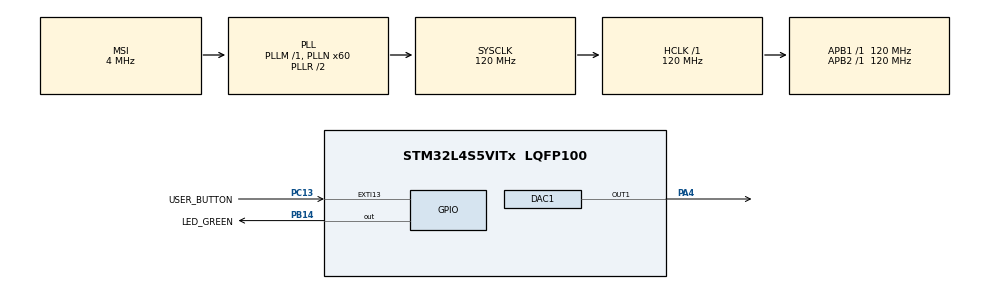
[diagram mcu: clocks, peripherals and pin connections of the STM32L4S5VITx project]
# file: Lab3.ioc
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DAC1.DAC_Trigger-DAC_OUT1=DAC_TRIGGER_T2_TRGO
Dma.DAC1_CH1.0.Direction=DMA_MEMORY_TO_PERIPH
Dma.DAC1_CH1.0.EventEnable=DISABLE
Dma.DAC1_CH1.0.Instance=DMA1_Channel1
Dma.DAC1_CH1.0.MemDataAlignment=DMA_MDATAALIGN_BYTE
Dma.DAC1_CH1.0.MemInc=DMA_MINC_ENABLE
Dma.DAC1_CH1.0.Mode=DMA_CIRCULAR
Dma.DAC1_CH1.0.PeriphDataAlignment=DMA_PDATAALIGN_HALFWORD
Dma.DAC1_CH1.0.PeriphInc=DMA_PINC_DISABLE
Dma.DAC1_CH1.0.Polarity=HAL_DMAMUX_REQUEST_GEN_RISING
Dma.DAC1_CH1.0.Priority=DMA_PRIORITY_LOW
Dma.DAC1_CH1.0.RequestNumber=1
Dma.DAC1_CH1.0.SignalID=NONE
Dma.DAC1_CH1.0.SyncEnable=DISABLE
Dma.DAC1_CH1.0.SyncPolarity=HAL_DMAMUX_SYNC_NO_EVENT
Dma.DAC1_CH1.0.SyncRequestNumber=1
Dma.DAC1_CH1.0.SyncSignalID=NONE
Dma.Request0=DAC1_CH1
Mcu.Family=STM32L4
Mcu.Name=STM32L4S5VITx
Mcu.Package=LQFP100
NVIC.DMA1_Channel1_IRQn=true\:0\:0\:false\:false\:true\:false\:true
NVIC.EXTI15_10_IRQn=true\:0\:0\:false\:false\:true\:true\:true
NVIC.PriorityGroup=NVIC_PRIORITYGROUP_4
NVIC.TIM2_IRQn=true\:0\:0\:false\:false\:true\:true\:true
PA13\ (JTMS/SWDIO).Signal=SYS_JTMS-SWDIO
PA4.Signal=COMP_DAC11_group
PB14.GPIO_Label=LED_GREEN
PB14.Signal=GPIO_Output
PB3\ (JTDO/TRACESWO).Signal=SYS_JTDO-SWO
PC13.GPIO_Label=USER_BUTTON
PC13.Signal=GPXTI13
ProjectManager.HeapSize=0x200
ProjectManager.StackSize=0x400
ProjectManager.TargetToolchain=STM32CubeIDE
RCC.ADCFreq_Value=48000000
RCC.AHBFreq_Value=120000000
RCC.APB1Freq_Value=120000000
RCC.APB1TimFreq_Value=120000000
RCC.APB2Freq_Value=120000000
RCC.APB2TimFreq_Value=120000000
RCC.CortexFreq_Value=120000000
RCC.HCLKFreq_Value=120000000
RCC.HSE_VALUE=8000000
RCC.HSI48_VALUE=48000000
RCC.HSI_VALUE=16000000
RCC.LSE_VALUE=32768
RCC.MSI_VALUE=4000000
RCC.PLLN=60
RCC.PLLSAI1N=24
RCC.SYSCLKFreq_VALUE=120000000
RCC.SYSCLKSource=RCC_SYSCLKSOURCE_PLLCLK
RCC.USBFreq_Value=48000000
RCC.VCOOutputFreq_Value=240000000
SH.COMP_DAC11_group.0=DAC1_OUT1,DAC_OUT1
TIM2.Period=2721
TIM2.TIM_MasterOutputTrigger=TIM_TRGO_UPDATE
VP_TIM2_VS_ClockSourceINT.Mode=Internal
board=B-L4S5I-IOT01A

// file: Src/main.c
/* USER CODE BEGIN Header */
/**
  ******************************************************************************
  * @file           : main.c
  * @brief          : Main program body
  ******************************************************************************
  * @attention
  *
  * <h2><center>&copy; Copyright (c) 2021 STMicroelectronics.
  * All rights reserved.</center></h2>
  *
  * This software component is licensed by ST under BSD 3-Clause license,
  * the "License"; You may not use this file except in compliance with the
  * License. You may obtain a copy of the License at:
  *                        opensource.org/licenses/BSD-3-Clause
  *
  ******************************************************************************
  */
/* USER CODE END Header */
#include "main.h"

/* USER CODE BEGIN Includes */
#include "arm_math.h"
/* USER CODE END Includes */

/* USER CODE BEGIN PD */
#define ITM_Port32(n) (*((volatile unsigned long *) (0xE0000000+4*n)))
uint8_t triangle;
uint8_t saw;
uint8_t sine;
// sample rate: 44.1kHz, system clock freq: 120MHz, counter period
#define first_sample_number 44	// 44.1kHz / 1kHz = 44, C6
#define second_sample_number 33	// 44.1kHz / 1.318kHz = 33, E6
#define third_sample_number 22 // 44.1kHz / 22 = 2.005kHz
#define buffer_length 132	// Buffer length
uint8_t first_array[buffer_length];	// This is the array used to store all C6 values in a period
uint8_t second_array[buffer_length]; // This is the array used to store all E6 values in a period
uint8_t third_array[buffer_length]; // This is the array used to store all values of the third frequency in a period
uint8_t buffer_array[buffer_length]; // This is the array used to store all buffer values in a period
int number = 0;	// This is the global variable to examine the current position
int tone = 0;	// This is the global variable to examine the current tone played
int currentTone = 3;	// This is the global variable to record the current tone
int previousButtonState = GPIO_PIN_RESET;	//This is the global variable to store the previous button state(not pressed)
/* USER CODE END PD */

DAC_HandleTypeDef hdac1;
DMA_HandleTypeDef hdma_dac1_ch1;

TIM_HandleTypeDef htim2;

void SystemClock_Config(void);
static void MX_GPIO_Init(void);
static void MX_DMA_Init(void);
static void MX_DAC1_Init(void);
static void MX_TIM2_Init(void);
/* USER CODE BEGIN PFP */
void HAL_GPIO_EXTI_Callback(uint16_t GPIO_Pin);
void HAL_TIM_PeriodElapsedCallback (TIM_HandleTypeDef * htim);
void HAL_DAC_ConvHalfCpltCallbackCh1(DAC_HandleTypeDef * hdac);
void HAL_DAC_ConvCpltCallbackCh1 (DAC_HandleTypeDef * hdac);
/* USER CODE END PFP */

int main(void)
{

  /* MCU Configuration--------------------------------------------------------*/

  /* Reset of all peripherals, Initializes the Flash interface and the Systick. */
  HAL_Init();

  /* Configure the system clock */
  SystemClock_Config();

  /* Initialize all configured peripherals */
  MX_GPIO_Init();
  MX_DMA_Init();
  MX_DAC1_Init();
  MX_TIM2_Init();
  /* USER CODE BEGIN 2 */
  // Part 2
  int loop = 0;
  float32_t counter = 0;
  float32_t radian = 0;
  float32_t temp = 0;
  for (loop = 0; loop < 3; loop++) {
	  for (counter = 0; counter < first_sample_number; counter++) {
	  	  radian = counter * 8.2 / 180 * PI;	// 360 / 44 = 8.2
	  	  temp = arm_sin_f32(radian); // -1 to 1
	  	  sine = (uint8_t)((temp + 1) * 127 * (2.0 / 3)); // change -1 to 1 to 0 to 2 then scale to 0 to 254, Scale your DAC values so they vary over about 2/3 of the possible dynamic range
	  	  first_array[44 * loop + (int)counter] = sine;
	    }
  }

  for (loop = 0; loop < 4; loop++) {
	  for (counter = 0; counter < second_sample_number; counter++) {
	  	  radian = counter * 10.9 / 180 * PI;	// 360 / 33 = 10.9
	  	  temp = arm_sin_f32(radian); // -1 to 1
	  	  sine = (uint8_t)((temp + 1) * 127 * (2.0 / 3)); // change -1 to 1 to 0 to 2 then scale to 0 to 254, Scale your DAC values so they vary over about 2/3 of the possible dynamic range
	  	  second_array[33 * loop + (int)counter] = sine;
	    }
  }

  for (loop = 0; loop < 6; loop++) {
	  for (counter = 0; counter < third_sample_number; counter++) {
	  	  radian = counter * 16.4 / 180 * PI;	// 360 / 22 = 16.4
	      temp = arm_sin_f32(radian); // -1 to 1
	      sine = (uint8_t)((temp + 1) * 127 * (2.0 / 3)); // change -1 to 1 to 0 to 2 then scale to 0 to 254, Scale your DAC values so they vary over about 2/3 of the possible dynamic range
	      third_array[22 * loop + (int)counter] = sine;
	    }
  }

  HAL_DAC_Start(&hdac1, DAC_CHANNEL_1); // ARD.D7
  HAL_DAC_Start(&hdac1, DAC_CHANNEL_2); // ARD.D13-SPI1_SCK/LED1
  HAL_TIM_Base_Start_IT(&htim2);
  /* USER CODE END 2 */

  /* Infinite loop */
  /* USER CODE BEGIN WHILE */
  while (1)
  {
	  // Part 1
	  // generate signal with a period of ~15ms
	  float32_t radian = 0;
	  float32_t temp = 0;
	  for (uint8_t counter = 0; counter < 16; counter++) { // Max should be 15 (15ms)
		  // triangle calculation
		  if (counter < 8) {
			  triangle = counter * 32; // 255/8 = 31.875
		  }
		  else if (counter == 8) {
			  triangle = 255; // max value for 8 bit
		  }
		  else {
			  triangle = (16 - counter) * 32;
		  }
		  // saw calculation
		  saw = counter * 17;	// 255/15ms = 17
		  radian = (float32_t)counter * 24 / 180 * PI; // 360/15 = 24
		  temp = arm_sin_f32(radian); // -1 to 1
		  sine = (uint8_t)((temp + 1) * 127); //change -1 to 1 to 0 to 2 then scale to 0 to 254
		  HAL_DAC_SetValue(&hdac1, DAC_CHANNEL_1,  DAC_ALIGN_8B_R, triangle);
		  HAL_DAC_SetValue(&hdac1, DAC_CHANNEL_2,  DAC_ALIGN_8B_R, saw);
		  HAL_DAC_SetValue(&hdac1, DAC_CHANNEL_1,  DAC_ALIGN_8B_R, sine);
		  HAL_Delay(0.4);
	  }

	  // Part 2 Step 1
//	  int currentButtonState = HAL_GPIO_ReadPin(USER_BUTTON_GPIO_Port, USER_BUTTON_Pin);
//	  if (currentButtonState != previousButtonState) {
//		  if (currentButtonState == GPIO_PIN_RESET) {
//			  HAL_GPIO_TogglePin(GPIOB, GPIO_PIN_14);
//		  }
//		  previousButtonState = currentButtonState;
//	  }
//
//	  // Part 2 Step 2
//
//	  if (HAL_DAC_GetState(&hdac1) == HAL_DAC_STATE_READY) {
//		  HAL_DAC_SetValue(&hdac1, DAC_CHANNEL_1,  DAC_ALIGN_8B_R, first_array[number]);
//	  }
//
//
//	  // Part 2 Step 4
//	  if (currentTone != tone) {
//		  HAL_DAC_Stop_DMA(&hdac1, DAC_CHANNEL_1);	// Stop the previous tone
//		  HAL_DAC_Start_DMA(&hdac1, DAC_CHANNEL_1, buffer_array, 132, DAC_ALIGN_8B_R);	// Play the next tone
//		  currentTone = tone;
//	  }

    /* USER CODE END WHILE */

  }
}

void SystemClock_Config(void)
{
  RCC_OscInitTypeDef RCC_OscInitStruct = {0};
  RCC_ClkInitTypeDef RCC_ClkInitStruct = {0};

  /** Configure the main internal regulator output voltage
  */
  if (HAL_PWREx_ControlVoltageScaling(PWR_REGULATOR_VOLTAGE_SCALE1_BOOST) != HAL_OK)
  {
    Error_Handler();
  }
  /** Initializes the RCC Oscillators according to the specified parameters
  * in the RCC_OscInitTypeDef structure.
  */
  RCC_OscInitStruct.OscillatorType = RCC_OSCILLATORTYPE_MSI;
  RCC_OscInitStruct.MSIState = RCC_MSI_ON;
  RCC_OscInitStruct.MSICalibrationValue = 0;
  RCC_OscInitStruct.MSIClockRange = RCC_MSIRANGE_6;
  RCC_OscInitStruct.PLL.PLLState = RCC_PLL_ON;
  RCC_OscInitStruct.PLL.PLLSource = RCC_PLLSOURCE_MSI;
  RCC_OscInitStruct.PLL.PLLM = 1;
  RCC_OscInitStruct.PLL.PLLN = 60;
  RCC_OscInitStruct.PLL.PLLP = RCC_PLLP_DIV2;
  RCC_OscInitStruct.PLL.PLLQ = RCC_PLLQ_DIV2;
  RCC_OscInitStruct.PLL.PLLR = RCC_PLLR_DIV2;
  if (HAL_RCC_OscConfig(&RCC_OscInitStruct) != HAL_OK)
  {
    Error_Handler();
  }
  /** Initializes the CPU, AHB and APB buses clocks
  */
  RCC_ClkInitStruct.ClockType = RCC_CLOCKTYPE_HCLK|RCC_CLOCKTYPE_SYSCLK
                              |RCC_CLOCKTYPE_PCLK1|RCC_CLOCKTYPE_PCLK2;
  RCC_ClkInitStruct.SYSCLKSource = RCC_SYSCLKSOURCE_PLLCLK;
  RCC_ClkInitStruct.AHBCLKDivider = RCC_SYSCLK_DIV1;
  RCC_ClkInitStruct.APB1CLKDivider = RCC_HCLK_DIV1;
  RCC_ClkInitStruct.APB2CLKDivider = RCC_HCLK_DIV1;

  if (HAL_RCC_ClockConfig(&RCC_ClkInitStruct, FLASH_LATENCY_5) != HAL_OK)
  {
    Error_Handler();
  }
}

static void MX_DAC1_Init(void)
{

  DAC_ChannelConfTypeDef sConfig = {0};

  /** DAC Initialization
  */
  hdac1.Instance = DAC1;
  if (HAL_DAC_Init(&hdac1) != HAL_OK)
  {
    Error_Handler();
  }
  /** DAC channel OUT1 config
  */
  sConfig.DAC_SampleAndHold = DAC_SAMPLEANDHOLD_DISABLE;
  sConfig.DAC_Trigger = DAC_TRIGGER_T2_TRGO;
  sConfig.DAC_HighFrequency = DAC_HIGH_FREQUENCY_INTERFACE_MODE_DISABLE;
  sConfig.DAC_OutputBuffer = DAC_OUTPUTBUFFER_ENABLE;
  sConfig.DAC_ConnectOnChipPeripheral = DAC_CHIPCONNECT_DISABLE;
  sConfig.DAC_UserTrimming = DAC_TRIMMING_FACTORY;
  if (HAL_DAC_ConfigChannel(&hdac1, &sConfig, DAC_CHANNEL_1) != HAL_OK)
  {
    Error_Handler();
  }

}

static void MX_TIM2_Init(void)
{

  TIM_ClockConfigTypeDef sClockSourceConfig = {0};
  TIM_MasterConfigTypeDef sMasterConfig = {0};

  htim2.Instance = TIM2;
  htim2.Init.Prescaler = 0;
  htim2.Init.CounterMode = TIM_COUNTERMODE_UP;
  htim2.Init.Period = 2721;
  htim2.Init.ClockDivision = TIM_CLOCKDIVISION_DIV1;
  htim2.Init.AutoReloadPreload = TIM_AUTORELOAD_PRELOAD_DISABLE;
  if (HAL_TIM_Base_Init(&htim2) != HAL_OK)
  {
    Error_Handler();
  }
  sClockSourceConfig.ClockSource = TIM_CLOCKSOURCE_INTERNAL;
  if (HAL_TIM_ConfigClockSource(&htim2, &sClockSourceConfig) != HAL_OK)
  {
    Error_Handler();
  }
  sMasterConfig.MasterOutputTrigger = TIM_TRGO_UPDATE;
  sMasterConfig.MasterSlaveMode = TIM_MASTERSLAVEMODE_DISABLE;
  if (HAL_TIMEx_MasterConfigSynchronization(&htim2, &sMasterConfig) != HAL_OK)
  {
    Error_Handler();
  }

}

static void MX_DMA_Init(void)
{

  /* DMA controller clock enable */
  __HAL_RCC_DMAMUX1_CLK_ENABLE();
  __HAL_RCC_DMA1_CLK_ENABLE();

  /* DMA interrupt init */
  /* DMA1_Channel1_IRQn interrupt configuration */
  HAL_NVIC_SetPriority(DMA1_Channel1_IRQn, 0, 0);
  HAL_NVIC_EnableIRQ(DMA1_Channel1_IRQn);

}

static void MX_GPIO_Init(void)
{
  GPIO_InitTypeDef GPIO_InitStruct = {0};

  /* GPIO Ports Clock Enable */
  __HAL_RCC_GPIOC_CLK_ENABLE();
  __HAL_RCC_GPIOA_CLK_ENABLE();
  __HAL_RCC_GPIOB_CLK_ENABLE();

  /*Configure GPIO pin Output Level */
  HAL_GPIO_WritePin(LED_GREEN_GPIO_Port, LED_GREEN_Pin, GPIO_PIN_RESET);

  /*Configure GPIO pin : USER_BUTTON_Pin */
  GPIO_InitStruct.Pin = USER_BUTTON_Pin;
  GPIO_InitStruct.Mode = GPIO_MODE_IT_RISING;
  GPIO_InitStruct.Pull = GPIO_NOPULL;
  HAL_GPIO_Init(USER_BUTTON_GPIO_Port, &GPIO_InitStruct);

  /*Configure GPIO pin : LED_GREEN_Pin */
  GPIO_InitStruct.Pin = LED_GREEN_Pin;
  GPIO_InitStruct.Mode = GPIO_MODE_OUTPUT_PP;
  GPIO_InitStruct.Pull = GPIO_NOPULL;
  GPIO_InitStruct.Speed = GPIO_SPEED_FREQ_LOW;
  HAL_GPIO_Init(LED_GREEN_GPIO_Port, &GPIO_InitStruct);

  /* EXTI interrupt init*/
  HAL_NVIC_SetPriority(EXTI15_10_IRQn, 0, 0);
  HAL_NVIC_EnableIRQ(EXTI15_10_IRQn);

}

/* USER CODE BEGIN 4 */
//void HAL_GPIO_EXTI_Callback(uint16_t GPIO_Pin) {	// detect when the button is pressed
//	if (GPIO_Pin == USER_BUTTON_Pin) {
//		HAL_GPIO_TogglePin(LED_GREEN_GPIO_Port, LED_GREEN_Pin);
//		tone++;
//		if (tone == 3) {
//			tone = 0;
//		}
//	}
//}
//
//void HAL_TIM_PeriodElapsedCallback(TIM_HandleTypeDef * htim) {	// What happens when timer reaches its counter number
//	if (htim == &htim2) {
//		number++;
//		if (number == buffer_length) {
//			number = 0;
//		}
//	}
//}
//
//void HAL_DAC_ConvHalfCpltCallbackCh1(DAC_HandleTypeDef * hdac) {	// load second half of the array
//	  if (tone == 0) {
//		  for (int i = 66; i < buffer_length; i++) {
//			  buffer_array[i] = first_array[i];
//		  }
//	  }
//	  else if (tone == 1) {
//		  for (int i = 66; i < buffer_length; i++) {
//			  buffer_array[i] = second_array[i];
//		  }
//	  }
//	  else if (tone == 2) {
//		  for (int i = 66; i < buffer_length; i++) {
//			  buffer_array[i] = third_array[i];
//		  }
//	  }
//}
//
//void HAL_DAC_ConvCpltCallbackCh1 (DAC_HandleTypeDef * hdac) {	// load first half of the array
//	  if (tone == 0) {
//		  for (int i = 0; i < buffer_length / 2; i++) {
//			  buffer_array[i] = first_array[i];
//		  }
//	  }
//	  else if (tone == 1) {
//		  for (int i = 0; i < buffer_length / 2; i++) {
//			  buffer_array[i] = second_array[i];
//		  }
//	  }
//	  else if (tone == 2) {
//		  for (int i = 0; i < buffer_length / 2; i++) {
//			  buffer_array[i] = third_array[i];
//		  }
//	  }
//}
/* USER CODE END 4 */

void Error_Handler(void)
{
  __disable_irq();
  while (1)
  {
  }
}

/************************ (C) COPYRIGHT STMicroelectronics *****END OF FILE****/
